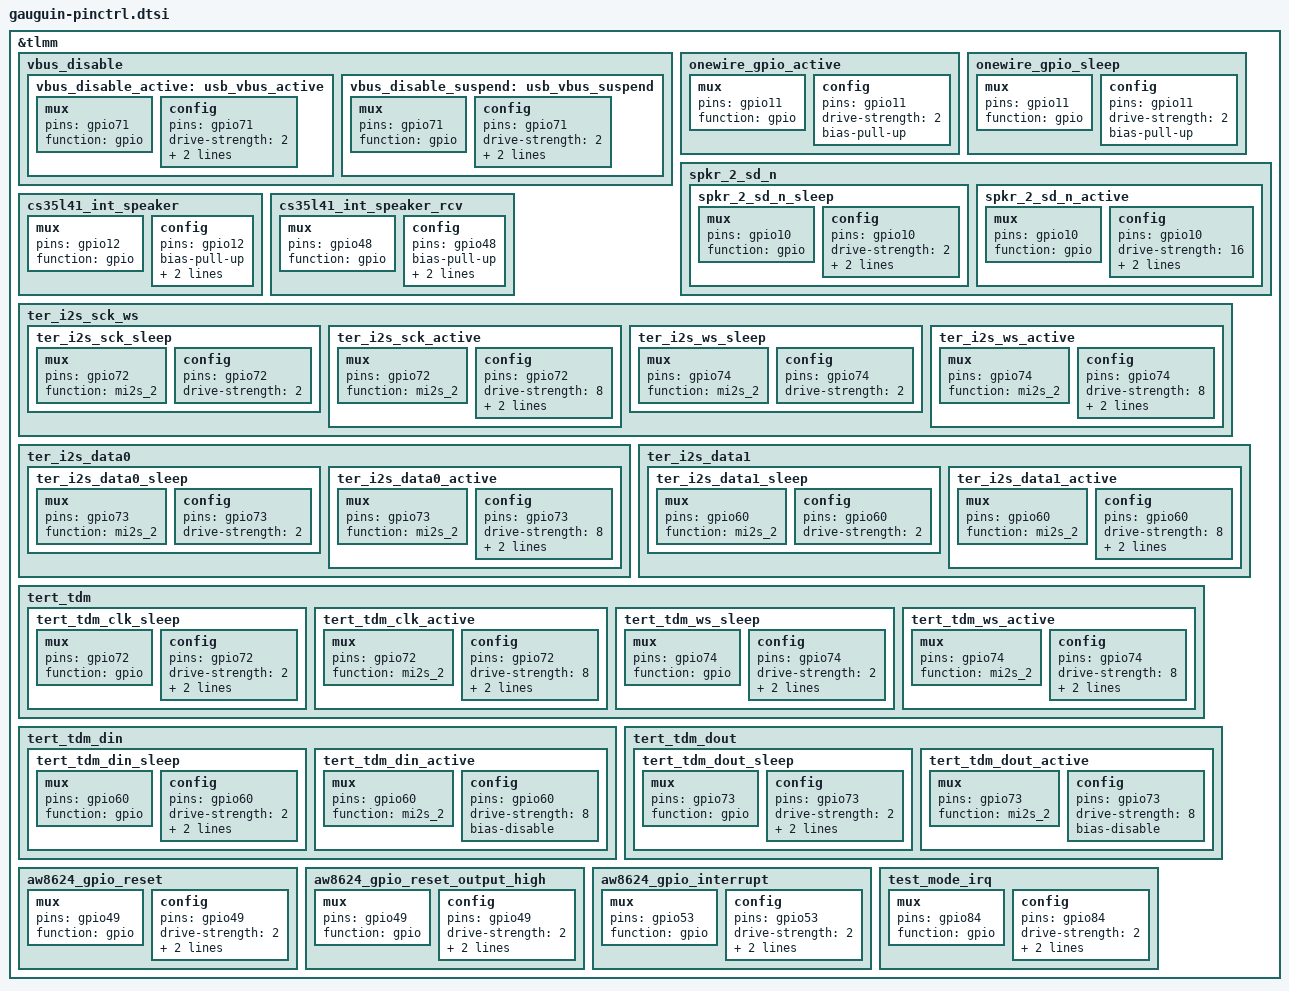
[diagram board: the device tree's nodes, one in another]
/*For J17 pinctrl overlay*/
&tlmm {
	vbus_disable {
		vbus_disable_active: usb_vbus_active {
			/* active state */
			mux {
				pins = "gpio71";
				function = "gpio";
			};

			config {
				pins = "gpio71";
				drive-strength = <2>; /* 2 MA */
				bias-pull-up;
				output-high;
			};
		};

		vbus_disable_suspend: usb_vbus_suspend {
			mux {
				pins = "gpio71";
				function = "gpio";
			};

			config {
				pins = "gpio71";
				drive-strength = <2>; /* 2 MA */
				bias-pull-down;
				output-low;
			};
		};
	};

	onewire_gpio_active: onewire_gpio_active {
		mux {
			pins = "gpio11";
			function = "gpio";
		};

		config {
			pins = "gpio11";
			drive-strength = <2>;
			bias-pull-up; /* No PULL */
		};
	};

	onewire_gpio_sleep: onewire_gpio_sleep {
		mux {
			pins = "gpio11";
			function = "gpio";
		};

		config {
			pins = "gpio11";
			drive-strength = <2>;
			bias-pull-up;
		};
	};

	spkr_2_sd_n {
		spkr_2_sd_n_sleep: spkr_2_sd_n_sleep {
			mux {
				pins = "gpio10";
				function = "gpio";
			};

			config {
				pins = "gpio10";
				drive-strength = <2>;   /* 2 mA */
				bias-pull-down;
				input-enable;
			};
		};

		spkr_2_sd_n_active: spkr_2_sd_n_active {
			mux {
				pins = "gpio10";
				function = "gpio";
			};

			config {
				pins = "gpio10";
				drive-strength = <16>;   /* 16 mA */
				bias-disable;
				output-high;
			};
		};
	};

	cs35l41_int_speaker: cs35l41_int_speaker {
			mux {
				pins = "gpio12";
				function = "gpio";
			};
			config {
				pins = "gpio12";
				bias-pull-up;
				drive-strength = <8>;
				input-enable;
			};
		};

	cs35l41_int_speaker_rcv: cs35l41_int_speaker_rcv {
		mux {
			pins = "gpio48";
			function = "gpio";
		};
		config {
			pins = "gpio48";
			bias-pull-up;
			drive-strength = <8>;
			input-enable;
		};
	};

	ter_i2s_sck_ws {
		ter_i2s_sck_sleep: ter_i2s_sck_sleep {
			mux {
				pins = "gpio72";
				function = "mi2s_2";
			};

			config {
				pins = "gpio72";
				drive-strength = <2>;   /* 2 mA */
			};
		};

		ter_i2s_sck_active: ter_i2s_sck_active {
			mux {
				pins = "gpio72";
				function = "mi2s_2";
			};

			config {
				pins = "gpio72";
				drive-strength = <8>;   /* 8 mA */
				bias-disable;
				output-high;
			};
		};

		ter_i2s_ws_sleep: ter_i2s_ws_sleep {
			mux {
				pins = "gpio74";
				function = "mi2s_2";
			};

			config {
				pins = "gpio74";
				drive-strength = <2>;   /* 2 mA */
			};
		};

		ter_i2s_ws_active: ter_i2s_ws_active {
			mux {
				pins = "gpio74";
				function = "mi2s_2";
			};

			config {
				pins = "gpio74";
				drive-strength = <8>;   /* 8 mA */
				bias-disable;
				output-high;
			};
		};
	};

	ter_i2s_data0 {
		ter_i2s_data0_sleep: ter_i2s_data0_sleep {
			mux {
				pins = "gpio73";
				function = "mi2s_2";
			};

			config {
				pins = "gpio73";
				drive-strength = <2>;   /* 2 mA */
			};
		};

		ter_i2s_data0_active: ter_i2s_data0_active {
			mux {
				pins = "gpio73";
				function = "mi2s_2";
			};

			config {
				pins = "gpio73";
				drive-strength = <8>;   /* 8 mA */
				bias-disable;
				input-enable;
			};
		};
	};

	ter_i2s_data1 {
		ter_i2s_data1_sleep: ter_i2s_data1_sleep {
			mux {
				pins = "gpio60";
				function = "mi2s_2";
			};

			config {
				pins = "gpio60";
				drive-strength = <2>;   /* 2 mA */
			};
		};

		ter_i2s_data1_active: ter_i2s_data1_active {
			mux {
				pins = "gpio60";
				function = "mi2s_2";
			};

			config {
				pins = "gpio60";
				drive-strength = <8>;   /* 8 mA */
				bias-disable;
				output-high;
			};
		};
	};

    tert_tdm {
		tert_tdm_clk_sleep: tert_tdm_clk_sleep {
			mux {
				pins = "gpio72";
				function = "gpio";
			};

			config {
				pins = "gpio72";
				drive-strength = <2>;   /* 2 mA */
				bias-pull-down;         /* PULL DOWN */
				input-enable;
			};
		};

		tert_tdm_clk_active: tert_tdm_clk_active {
			mux {
				pins = "gpio72";
				function = "mi2s_2";
			};

			config {
				pins = "gpio72";
				drive-strength = <8>;   /* 8 mA */
				bias-disable;           /* NO PULL */
				output-high;
			};
		};

		tert_tdm_ws_sleep: tert_tdm_ws_sleep {
			mux {
				pins = "gpio74";
				function = "gpio";
			};

			config {
				pins = "gpio74";
				drive-strength = <2>;   /* 2 mA */
				bias-pull-down;         /* PULL DOWN */
				input-enable;
			};
		};

		tert_tdm_ws_active: tert_tdm_ws_active {
			mux {
				pins = "gpio74";
				function = "mi2s_2";
			};

			config {
				pins = "gpio74";
				drive-strength = <8>;   /* 8 mA */
				bias-disable;           /* NO PULL */
				output-high;
			};
		};
	};

	tert_tdm_din {
		tert_tdm_din_sleep: tert_tdm_din_sleep {
			mux {
				pins = "gpio60";
				function = "gpio";
			};

			config {
				pins = "gpio60";
				drive-strength = <2>;   /* 2 mA */
				bias-pull-down;         /* PULL DOWN */
				input-enable;
			};
		};

		tert_tdm_din_active: tert_tdm_din_active {
			mux {
				pins = "gpio60";
				function = "mi2s_2";
			};

			config {
				pins = "gpio60";
				drive-strength = <8>;   /* 8 mA */
				bias-disable;           /* NO PULL */
			};
		};
	};

	tert_tdm_dout {
		tert_tdm_dout_sleep: tert_tdm_dout_sleep {
			mux {
				pins = "gpio73";
				function = "gpio";
			};

			config {
				pins = "gpio73";
				drive-strength = <2>;   /* 2 mA */
				bias-pull-down;         /* PULL DOWN */
				input-enable;
			};
		};

		tert_tdm_dout_active: tert_tdm_dout_active {
			mux {
				pins = "gpio73";
				function = "mi2s_2";
			};

			config {
				pins = "gpio73";
				drive-strength = <8>;   /* 8 mA */
				bias-disable;           /* NO PULL */
			};
		};
	};

	/* AW8624_RESET_N */
	aw8624_gpio_reset: aw8624_gpio_reset {
		mux {
			pins = "gpio49";
			function = "gpio";
		};
		config {
			pins = "gpio49";
			drive-strength = <2>;
			bias-disable;
			output-low;
		};
	};
	/* AW8624_RESET_N, state device active*/
	aw8624_gpio_reset_output_high: aw8624_gpio_reset_output_high {
		mux {
			pins = "gpio49";
			function = "gpio";
		};
		config {
			pins = "gpio49";
			drive-strength = <2>;
			bias-disable;
			output-high;
		};
	};
	/* AW8624_INTERRUPT_N */
	aw8624_gpio_interrupt: aw8624_gpio_interrupt {
		mux {
			pins = "gpio53";
			function = "gpio";
		};
		config {
			pins = "gpio53";
			drive-strength = <2>;
			bias-pull-up;
			input-enable;
		};
	};

	test_mode_irq: test_mode_irq {
		mux {
			pins = "gpio84";
			function = "gpio";
		};

		config {
			pins = "gpio84";
			drive-strength = <2>;
			bias-pull-up;
			input-enable;
		};
	};
};
